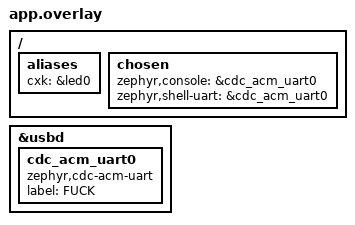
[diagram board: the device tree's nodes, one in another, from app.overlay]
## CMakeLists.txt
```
cmake_minimum_required(VERSION 3.20.0)

set(BOARD rpi_pico2/rp2350a/m33)
find_package(Zephyr)
project(helloworld)
zephyr_compile_options(-w)  # -w 表示禁止所有警告
target_sources(app PRIVATE src/main.c)
```

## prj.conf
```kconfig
# 启用USB设备栈
CONFIG_USB_DEVICE_STACK=y

# 可选：设置USB设备描述符，让设备在主机上显示为友好的名称
CONFIG_USB_DEVICE_PRODUCT="Pico 2 USB Serial"
CONFIG_USB_DEVICE_VID=0x2E8A
CONFIG_USB_DEVICE_PID=0x000a

# 对于总线供电设备（如Pico 2），此项必须设为 'n'
CONFIG_USB_SELF_POWERED=n

# 确保USB设备在启动时初始化
CONFIG_USB_DEVICE_INITIALIZE_AT_BOOT=y

# 启用串行驱动器和控制台功能
CONFIG_SERIAL=y
CONFIG_CONSOLE=y
CONFIG_UART_CONSOLE=y

# 启用UART线路控制，这对于CDC ACM设备是必需的
CONFIG_UART_LINE_CTRL=y

# 如果需要，可以启用日志功能
CONFIG_LOG=y
```

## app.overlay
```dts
/
{
	aliases{
		cxk=&led0;
	};
	chosen {
		zephyr,console = &cdc_acm_uart0;
		zephyr,shell-uart = &cdc_acm_uart0;
	};
};
	&usbd {
		cdc_acm_uart0:cdc_acm_uart0{
			compatible = "zephyr,cdc-acm-uart";
			label = "FUCK";
			status = "okay";
		};
	};
```

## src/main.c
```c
#include <zephyr/kernel.h>
#include <zephyr/device.h>
#include <zephyr/drivers/gpio.h>
#include <zephyr/sys/printk.h>
#include <zephyr/logging/log.h>

LOG_MODULE_REGISTER(MAIN,3);
static const struct device *const usb_uart = DEVICE_DT_GET(DT_NODELABEL(cdc_acm_uart0));

static struct gpio_dt_spec led = GPIO_DT_SPEC_GET_OR(DT_ALIAS(cxk), gpios,
						     {0});

int main(void)
{
	if(!device_is_ready(usb_uart));
	if(!device_is_ready(led.port))
	{
		LOG_ERR("What fucking");
		return 0;
	}
	printk("%s",led.port->name);
	gpio_pin_configure_dt(&led,GPIO_OUTPUT_INACTIVE);
	while (1)
	{
		gpio_pin_set_dt(&led,1);
		k_sleep(K_MSEC(500));
		gpio_pin_set_dt(&led,0);
		k_sleep(K_MSEC(500));
		printk("Fuck,m3\n");
	}
	
	return 0;
}
```
